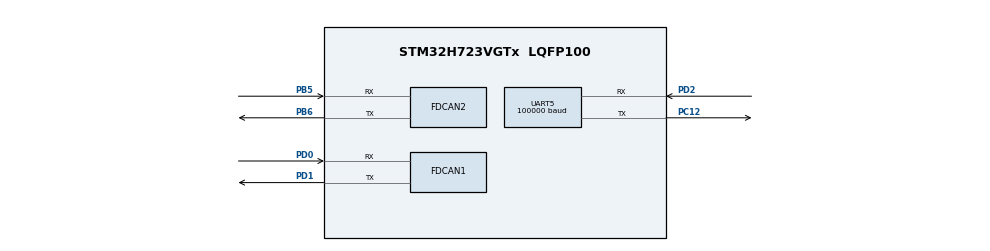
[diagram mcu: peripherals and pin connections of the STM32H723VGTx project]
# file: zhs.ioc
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Dma.Request0=UART5_RX
Dma.UART5_RX.0.Direction=DMA_PERIPH_TO_MEMORY
Dma.UART5_RX.0.EventEnable=DISABLE
Dma.UART5_RX.0.FIFOMode=DMA_FIFOMODE_DISABLE
Dma.UART5_RX.0.Instance=DMA1_Stream2
Dma.UART5_RX.0.MemDataAlignment=DMA_MDATAALIGN_BYTE
Dma.UART5_RX.0.MemInc=DMA_MINC_ENABLE
Dma.UART5_RX.0.Mode=DMA_NORMAL
Dma.UART5_RX.0.PeriphDataAlignment=DMA_PDATAALIGN_BYTE
Dma.UART5_RX.0.PeriphInc=DMA_PINC_DISABLE
Dma.UART5_RX.0.Polarity=HAL_DMAMUX_REQ_GEN_RISING
Dma.UART5_RX.0.Priority=DMA_PRIORITY_HIGH
Dma.UART5_RX.0.RequestNumber=1
Dma.UART5_RX.0.SignalID=NONE
Dma.UART5_RX.0.SyncEnable=DISABLE
Dma.UART5_RX.0.SyncPolarity=HAL_DMAMUX_SYNC_NO_EVENT
Dma.UART5_RX.0.SyncRequestNumber=1
Dma.UART5_RX.0.SyncSignalID=NONE
FDCAN1.CalculateBaudRateNominal=1000000
FDCAN1.CalculateTimeBitNominal=1000
FDCAN1.CalculateTimeQuantumNominal=12.5
FDCAN1.DataSyncJumpWidth=2
FDCAN1.DataTimeSeg1=13
FDCAN1.DataTimeSeg2=2
FDCAN1.ExtFiltersNbr=4
FDCAN1.NominalPrescaler=1
FDCAN1.NominalSyncJumpWidth=20
FDCAN1.NominalTimeSeg1=59
FDCAN1.NominalTimeSeg2=20
FDCAN1.RxBuffersNbr=2
FDCAN1.RxFifo0ElmtsNbr=8
FDCAN1.RxFifo1ElmtsNbr=8
FDCAN1.StdFiltersNbr=4
FDCAN1.TxBuffersNbr=8
FDCAN1.TxEventsNbr=8
FDCAN1.TxFifoQueueElmtsNbr=8
FDCAN2.CalculateBaudRateNominal=1000000
FDCAN2.CalculateTimeBitNominal=1000
FDCAN2.CalculateTimeQuantumNominal=12.5
FDCAN2.DataSyncJumpWidth=2
FDCAN2.DataTimeSeg1=13
FDCAN2.DataTimeSeg2=2
FDCAN2.ExtFiltersNbr=4
FDCAN2.MessageRAMOffset=0x406
FDCAN2.NominalPrescaler=1
FDCAN2.NominalSyncJumpWidth=20
FDCAN2.NominalTimeSeg1=59
FDCAN2.NominalTimeSeg2=20
FDCAN2.RxBuffersNbr=2
FDCAN2.RxFifo0ElmtsNbr=8
FDCAN2.RxFifo1ElmtsNbr=8
FDCAN2.StdFiltersNbr=4
FDCAN2.TxBuffersNbr=8
FDCAN2.TxEventsNbr=8
FDCAN2.TxFifoQueueElmtsNbr=8
FREERTOS.INCLUDE_eTaskGetState=1
FREERTOS.INCLUDE_vTaskDelayUntil=1
FREERTOS.Tasks01=defaultTask,0,128,TaskInit,As weak,NULL,Dynamic,NULL,NULL
Mcu.Family=STM32H7
Mcu.Name=STM32H723VGTx
Mcu.Package=LQFP100
NVIC.DMA1_Stream2_IRQn=true\:5\:0\:false\:false\:true\:true\:false\:true\:true
NVIC.FDCAN1_IT0_IRQn=true\:5\:0\:false\:false\:true\:true\:true\:true\:true
NVIC.FDCAN1_IT1_IRQn=true\:5\:0\:false\:false\:true\:true\:true\:true\:true
NVIC.FDCAN2_IT0_IRQn=true\:5\:0\:false\:false\:true\:true\:true\:true\:true
NVIC.FDCAN2_IT1_IRQn=true\:5\:0\:false\:false\:true\:true\:true\:true\:true
NVIC.PriorityGroup=NVIC_PRIORITYGROUP_4
NVIC.TIM1_UP_IRQn=true\:15\:0\:false\:false\:true\:false\:false\:true\:true
NVIC.TimeBase=TIM1_UP_IRQn
NVIC.TimeBaseIP=TIM1
NVIC.UART5_IRQn=true\:5\:0\:false\:false\:true\:true\:true\:true\:true
PB5.Mode=FDCAN_Activate
PB5.Signal=FDCAN2_RX
PB6.Mode=FDCAN_Activate
PB6.Signal=FDCAN2_TX
PC12.Mode=Asynchronous
PC12.Signal=UART5_TX
PD0.Mode=FDCAN_Activate
PD0.Signal=FDCAN1_RX
PD1.Mode=FDCAN_Activate
PD1.Signal=FDCAN1_TX
PD2.Mode=Asynchronous
PD2.Signal=UART5_RX
PH0-OSC_IN.Mode=HSE-External-Oscillator
PH0-OSC_IN.Signal=RCC_OSC_IN
PH1-OSC_OUT.Mode=HSE-External-Oscillator
PH1-OSC_OUT.Signal=RCC_OSC_OUT
ProjectManager.HeapSize=0x200
ProjectManager.StackSize=0x400
ProjectManager.TargetToolchain=MDK-ARM V5.32
RCC.ADCFreq_Value=129000000
RCC.APB1Freq_Value=120000000
RCC.APB2Freq_Value=120000000
RCC.APB3Freq_Value=120000000
RCC.APB4Freq_Value=120000000
RCC.CortexFreq_Value=240000000
RCC.D1PPRE=RCC_APB3_DIV2
RCC.D2PPRE1=RCC_APB1_DIV2
RCC.D2PPRE2=RCC_APB2_DIV2
RCC.D3PPRE=RCC_APB4_DIV2
RCC.DIVM1=4
RCC.DIVN1=15
RCC.DIVP1=1
RCC.DIVQ1=3
RCC.HCLKFreq_Value=240000000
RCC.HSE_VALUE=24000000
RCC.PLLFRACN=0
RCC.SYSCLKFreq_VALUE=240000000
RCC.SYSCLKSource=RCC_SYSCLKSOURCE_PLLCLK
RCC.USBFreq_Value=80000000
UART5.BaudRate=100000
UART5.DMADisableonRxErrorParam=UART_ADVFEATURE_DMA_ENABLEONRXERROR
UART5.MSBFirstParam=UART_ADVFEATURE_MSBFIRST_DISABLE
UART5.OverrunDisableParam=UART_ADVFEATURE_OVERRUN_DISABLE
UART5.Parity=PARITY_EVEN
UART5.RXFIFOThreshold=RXFIFO_THRESHOLD_FULL
UART5.StopBits=UART_STOPBITS_2
UART5.TXFIFOThreshold=TXFIFO_THRESHOLD_EMPTY
UART5.WordLength=WORDLENGTH_9B
VP_FREERTOS_VS_CMSIS_V1.Mode=CMSIS_V1
VP_MEMORYMAP_VS_MEMORYMAP.Mode=CurAppReg
VP_SYS_VS_tim1.Mode=TIM1
board=custom

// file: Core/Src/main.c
/* USER CODE BEGIN Header */
/**
  ******************************************************************************
  * @file           : main.c
  * @brief          : Main program body
  ******************************************************************************
  * @attention
  *
  * Copyright (c) 2025 STMicroelectronics.
  * All rights reserved.
  *
  * This software is licensed under terms that can be found in the LICENSE file
  * in the root directory of this software component.
  * If no LICENSE file comes with this software, it is provided AS-IS.
  *
  ******************************************************************************
  */
/* USER CODE END Header */
#include "main.h"
#include "cmsis_os.h"
#include "dma.h"
#include "fdcan.h"
#include "usart.h"
#include "gpio.h"

void SystemClock_Config(void);
void MX_FREERTOS_Init(void);

int main(void)
{

  /* MCU Configuration--------------------------------------------------------*/

  /* Reset of all peripherals, Initializes the Flash interface and the Systick. */
  HAL_Init();

  /* Configure the system clock */
  SystemClock_Config();

  /* Initialize all configured peripherals */
  MX_GPIO_Init();
  MX_DMA_Init();
  MX_FDCAN1_Init();
  MX_FDCAN2_Init();
  MX_UART5_Init();

  /* Call init function for freertos objects (in cmsis_os2.c) */
  MX_FREERTOS_Init();

  /* Start scheduler */
  osKernelStart();

  /* We should never get here as control is now taken by the scheduler */

  /* Infinite loop */
  while (1)
  {

  }
}

void SystemClock_Config(void)
{
  RCC_OscInitTypeDef RCC_OscInitStruct = {0};
  RCC_ClkInitTypeDef RCC_ClkInitStruct = {0};

  /** Supply configuration update enable
  */
  HAL_PWREx_ConfigSupply(PWR_LDO_SUPPLY);

  /** Configure the main internal regulator output voltage
  */
  __HAL_PWR_VOLTAGESCALING_CONFIG(PWR_REGULATOR_VOLTAGE_SCALE0);

  while(!__HAL_PWR_GET_FLAG(PWR_FLAG_VOSRDY)) {}

  /** Initializes the RCC Oscillators according to the specified parameters
  * in the RCC_OscInitTypeDef structure.
  */
  RCC_OscInitStruct.OscillatorType = RCC_OSCILLATORTYPE_HSI;
  RCC_OscInitStruct.HSIState = RCC_HSI_DIV1;
  RCC_OscInitStruct.HSICalibrationValue = 64;
  RCC_OscInitStruct.PLL.PLLState = RCC_PLL_ON;
  RCC_OscInitStruct.PLL.PLLSource = RCC_PLLSOURCE_HSI;
  RCC_OscInitStruct.PLL.PLLM = 4;
  RCC_OscInitStruct.PLL.PLLN = 15;
  RCC_OscInitStruct.PLL.PLLP = 1;
  RCC_OscInitStruct.PLL.PLLQ = 3;
  RCC_OscInitStruct.PLL.PLLR = 2;
  RCC_OscInitStruct.PLL.PLLRGE = RCC_PLL1VCIRANGE_3;
  RCC_OscInitStruct.PLL.PLLVCOSEL = RCC_PLL1VCOWIDE;
  RCC_OscInitStruct.PLL.PLLFRACN = 0;
  if (HAL_RCC_OscConfig(&RCC_OscInitStruct) != HAL_OK)
  {
    Error_Handler();
  }

  /** Initializes the CPU, AHB and APB buses clocks
  */
  RCC_ClkInitStruct.ClockType = RCC_CLOCKTYPE_HCLK|RCC_CLOCKTYPE_SYSCLK
                              |RCC_CLOCKTYPE_PCLK1|RCC_CLOCKTYPE_PCLK2
                              |RCC_CLOCKTYPE_D3PCLK1|RCC_CLOCKTYPE_D1PCLK1;
  RCC_ClkInitStruct.SYSCLKSource = RCC_SYSCLKSOURCE_PLLCLK;
  RCC_ClkInitStruct.SYSCLKDivider = RCC_SYSCLK_DIV1;
  RCC_ClkInitStruct.AHBCLKDivider = RCC_HCLK_DIV1;
  RCC_ClkInitStruct.APB3CLKDivider = RCC_APB3_DIV2;
  RCC_ClkInitStruct.APB1CLKDivider = RCC_APB1_DIV2;
  RCC_ClkInitStruct.APB2CLKDivider = RCC_APB2_DIV2;
  RCC_ClkInitStruct.APB4CLKDivider = RCC_APB4_DIV2;

  if (HAL_RCC_ClockConfig(&RCC_ClkInitStruct, FLASH_LATENCY_3) != HAL_OK)
  {
    Error_Handler();
  }
}

void HAL_TIM_PeriodElapsedCallback(TIM_HandleTypeDef *htim)
{
  if (htim->Instance == TIM1)
  {
    HAL_IncTick();
  }
}

void Error_Handler(void)
{
  __disable_irq();
  while (1)
  {
  }
}

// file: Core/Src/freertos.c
/* USER CODE BEGIN Header */
/**
  ******************************************************************************
  * File Name          : freertos.c
  * Description        : Code for freertos applications
  ******************************************************************************
  * @attention
  *
  * Copyright (c) 2025 STMicroelectronics.
  * All rights reserved.
  *
  * This software is licensed under terms that can be found in the LICENSE file
  * in the root directory of this software component.
  * If no LICENSE file comes with this software, it is provided AS-IS.
  *
  ******************************************************************************
  */
/* USER CODE END Header */

#include "FreeRTOS.h"
#include "task.h"
#include "main.h"
#include "cmsis_os.h"

/* USER CODE BEGIN Includes */
#include "task_runtime.h"
/* USER CODE END Includes */

osThreadId defaultTaskHandle;

void TaskInit(void const * argument);

void MX_FREERTOS_Init(void); /* (MISRA C 2004 rule 8.1) */

/* GetIdleTaskMemory prototype (linked to static allocation support) */
void vApplicationGetIdleTaskMemory( StaticTask_t **ppxIdleTaskTCBBuffer, StackType_t **ppxIdleTaskStackBuffer, uint32_t *pulIdleTaskStackSize );

/* USER CODE BEGIN GET_IDLE_TASK_MEMORY */
static StaticTask_t xIdleTaskTCBBuffer;
static StackType_t xIdleStack[configMINIMAL_STACK_SIZE];

void vApplicationGetIdleTaskMemory( StaticTask_t **ppxIdleTaskTCBBuffer, StackType_t **ppxIdleTaskStackBuffer, uint32_t *pulIdleTaskStackSize )
{
  *ppxIdleTaskTCBBuffer = &xIdleTaskTCBBuffer;
  *ppxIdleTaskStackBuffer = &xIdleStack[0];
  *pulIdleTaskStackSize = configMINIMAL_STACK_SIZE;
  /* place for user code */
}
/* USER CODE END GET_IDLE_TASK_MEMORY */

void MX_FREERTOS_Init(void) {

  /* Create the thread(s) */
  /* definition and creation of defaultTask */
  osThreadDef(defaultTask, TaskInit, osPriorityNormal, 0, 128);
  defaultTaskHandle = osThreadCreate(osThread(defaultTask), NULL);

}

__weak void TaskInit(void const * argument)
{
  for(;;)
  {
    osDelay(1);
  }
}
